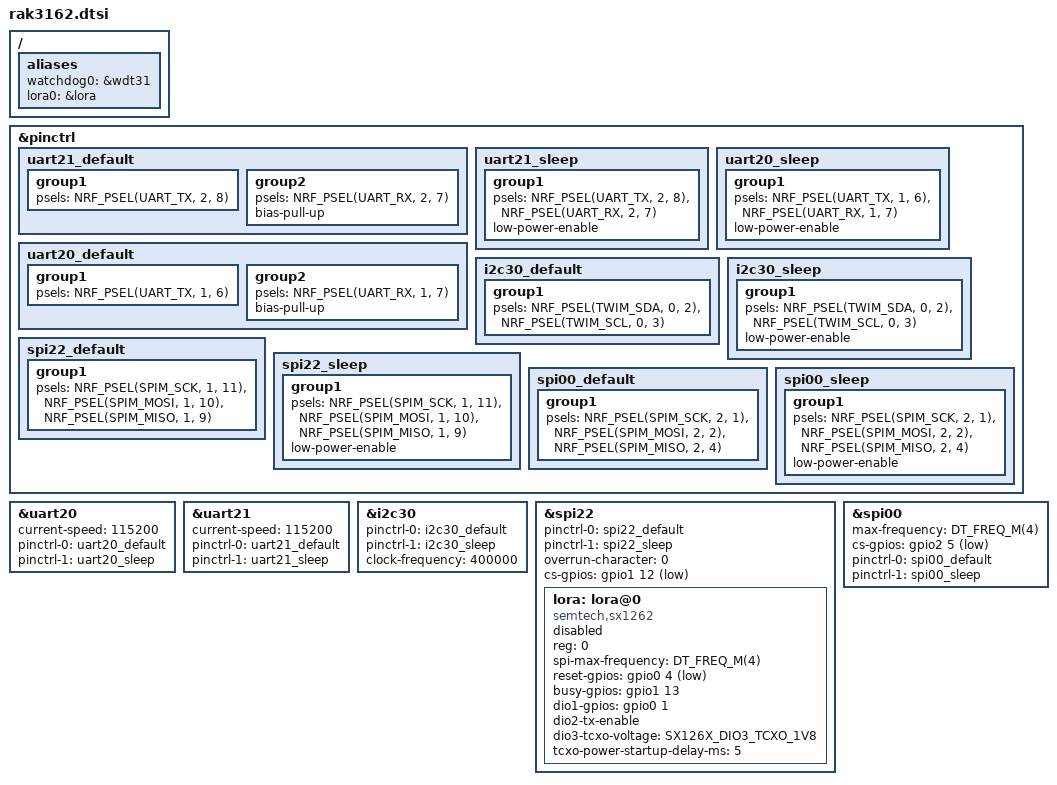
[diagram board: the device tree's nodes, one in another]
/*
 * SPDX-License-Identifier: Apache-2.0
 * Copyright (c) 2026 RAKwireless Technology Limited
 *
 * RAK3162 module pinout description
 * https://docs.rakwireless.com/Product-Categories/WisDuo/RAK3162/Overview/
 *
 * P1  - ANT_SW (P0.00)
 * P2  - DIO1 (P0.01)
 * P3  - I2C_SDA (P0.02)
 * P4  - I2C_SCL (P0.03)
 * P5  - SX1262_RESET (P0.04)
 * ...
 * UART0 (debug): TX=P1.06, RX=P1.07
 * UART1:         TX=P2.08, RX=P2.07
 * LoRa SPI:      SCK=P1.11, MOSI=P1.10, MISO=P1.09, CS=P1.12
 * Ext SPI:       SCK=P2.01, MOSI=P2.02, MISO=P2.04, CS=P2.05
 * WisBlock LED1=P2.09, LED2=P2.10
 */

#include <nordic/nrf54l15_cpuapp.dtsi>
#include <zephyr/dt-bindings/lora/sx126x.h>
#include <zephyr/dt-bindings/pinctrl/nrf-pinctrl.h>

&pinctrl {
	/omit-if-no-ref/ uart21_default: uart21_default {
		group1 {
			psels = <NRF_PSEL(UART_TX, 2, 8)>;
		};
		group2 {
			psels = <NRF_PSEL(UART_RX, 2, 7)>;
			bias-pull-up;
		};
	};

	/omit-if-no-ref/ uart21_sleep: uart21_sleep {
		group1 {
			psels = <NRF_PSEL(UART_TX, 2, 8)>,
				<NRF_PSEL(UART_RX, 2, 7)>;
			low-power-enable;
		};
	};

	/omit-if-no-ref/ uart20_default: uart20_default {
		group1 {
			psels = <NRF_PSEL(UART_TX, 1, 6)>;
		};
		group2 {
			psels = <NRF_PSEL(UART_RX, 1, 7)>;
			bias-pull-up;
		};
	};

	/omit-if-no-ref/ uart20_sleep: uart20_sleep {
		group1 {
			psels = <NRF_PSEL(UART_TX, 1, 6)>,
				<NRF_PSEL(UART_RX, 1, 7)>;
			low-power-enable;
		};
	};

	/omit-if-no-ref/ i2c30_default: i2c30_default {
		group1 {
			psels = <NRF_PSEL(TWIM_SDA, 0, 2)>,
				<NRF_PSEL(TWIM_SCL, 0, 3)>;
		};
	};

	/omit-if-no-ref/ i2c30_sleep: i2c30_sleep {
		group1 {
			psels = <NRF_PSEL(TWIM_SDA, 0, 2)>,
				<NRF_PSEL(TWIM_SCL, 0, 3)>;
			low-power-enable;
		};
	};

	/omit-if-no-ref/ spi22_default: spi22_default {
		group1 {
			psels = <NRF_PSEL(SPIM_SCK,  1, 11)>,
				<NRF_PSEL(SPIM_MOSI, 1, 10)>,
				<NRF_PSEL(SPIM_MISO, 1,  9)>;
		};
	};

	/omit-if-no-ref/ spi22_sleep: spi22_sleep {
		group1 {
			psels = <NRF_PSEL(SPIM_SCK,  1, 11)>,
				<NRF_PSEL(SPIM_MOSI, 1, 10)>,
				<NRF_PSEL(SPIM_MISO, 1,  9)>;
			low-power-enable;
		};
	};

	/omit-if-no-ref/ spi00_default: spi00_default {
		group1 {
			psels = <NRF_PSEL(SPIM_SCK,  2, 1)>,
				<NRF_PSEL(SPIM_MOSI, 2, 2)>,
				<NRF_PSEL(SPIM_MISO, 2, 4)>;
		};
	};

	/omit-if-no-ref/ spi00_sleep: spi00_sleep {
		group1 {
			psels = <NRF_PSEL(SPIM_SCK,  2, 1)>,
				<NRF_PSEL(SPIM_MOSI, 2, 2)>,
				<NRF_PSEL(SPIM_MISO, 2, 4)>;
			low-power-enable;
		};
	};
};

/ {
	aliases {
		watchdog0 = &wdt31;
		lora0 = &lora;
	};
};

&uart20 {
	current-speed = <115200>;
	pinctrl-0 = <&uart20_default>;
	pinctrl-1 = <&uart20_sleep>;
	pinctrl-names = "default", "sleep";
};

&uart21 {
	current-speed = <115200>;
	pinctrl-0 = <&uart21_default>;
	pinctrl-1 = <&uart21_sleep>;
	pinctrl-names = "default", "sleep";
};

&i2c30 {
	pinctrl-0 = <&i2c30_default>;
	pinctrl-1 = <&i2c30_sleep>;
	pinctrl-names = "default", "sleep";
	clock-frequency = <400000>;
};

&spi22 {
	pinctrl-0 = <&spi22_default>;
	pinctrl-1 = <&spi22_sleep>;
	pinctrl-names = "default", "sleep";
	overrun-character = <0>;
	cs-gpios = <&gpio1 12 GPIO_ACTIVE_LOW>;

	lora: lora@0 {
		compatible = "semtech,sx1262";
		reg = <0>;
		status = "disabled";
		spi-max-frequency = <DT_FREQ_M(4)>;
		reset-gpios = <&gpio0 4 GPIO_ACTIVE_LOW>;
		busy-gpios  = <&gpio1 13 GPIO_ACTIVE_HIGH>;
		dio1-gpios  = <&gpio0 1 (GPIO_ACTIVE_HIGH | GPIO_PULL_DOWN)>;
		dio2-tx-enable;
		dio3-tcxo-voltage = <SX126X_DIO3_TCXO_1V8>;
		tcxo-power-startup-delay-ms = <5>;
	};
};

&spi00 {
	max-frequency = <DT_FREQ_M(4)>;
	cs-gpios = <&gpio2 5 GPIO_ACTIVE_LOW>;
	pinctrl-0 = <&spi00_default>;
	pinctrl-1 = <&spi00_sleep>;
	pinctrl-names = "default", "sleep";
};
